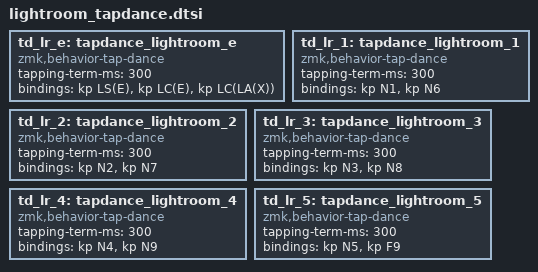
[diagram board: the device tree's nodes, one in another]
/*****************************************************************************************************
 *  TAP DANCE configurations
 *  for LIGHTROOM special cases
 *****************************************************************************************************/
#include <dt-bindings/zmk/keys.h>

// to INCLUDE inside Behaviors section of Keymap where other dependencies already pre-included like Layer #def constants

td_lr_e: tapdance_lightroom_e {
    // (1x) Shift+E (toggle preview window)
    // (2x) Ctrl+E (edit in Photoshop)
    // (3x) Ctrl+Alt+X (open as SmartObject in PS)
    compatible = "zmk,behavior-tap-dance";
    #binding-cells = <0>;
    tapping-term-ms = <300>;
    bindings = <&kp LS(E)>, <&kp LC(E)>, <&kp LC(LA(X))>;
};

// --------------------------------------------------
// Lightroom N1 - N5 keys:
// 1-tap for 1-2-3-4-5 (stars), 2x-tap for 6-7-8-9-F9 (colors, F9 does AHK to nav Lightroom menus for purple)
// [ ] TODO: C-macro-ify to reduce repetition? {namepart, K1, K2}

td_lr_1: tapdance_lightroom_1 {
    compatible = "zmk,behavior-tap-dance";
    #binding-cells = <0>;
    tapping-term-ms = <300>;
    bindings = <&kp N1>, <&kp N6>;
};

td_lr_2: tapdance_lightroom_2 {
    compatible = "zmk,behavior-tap-dance";
    #binding-cells = <0>;
    tapping-term-ms = <300>;
    bindings = <&kp N2>, <&kp N7>;
};

td_lr_3: tapdance_lightroom_3 {
    compatible = "zmk,behavior-tap-dance";
    #binding-cells = <0>;
    tapping-term-ms = <300>;
    bindings = <&kp N3>, <&kp N8>;
};

td_lr_4: tapdance_lightroom_4 {
    compatible = "zmk,behavior-tap-dance";
    #binding-cells = <0>;
    tapping-term-ms = <300>;
    bindings = <&kp N4>, <&kp N9>;
};

td_lr_5: tapdance_lightroom_5 {
    compatible = "zmk,behavior-tap-dance";
    #binding-cells = <0>;
    tapping-term-ms = <300>;
    bindings = <&kp N5>, <&kp F9>;
};
